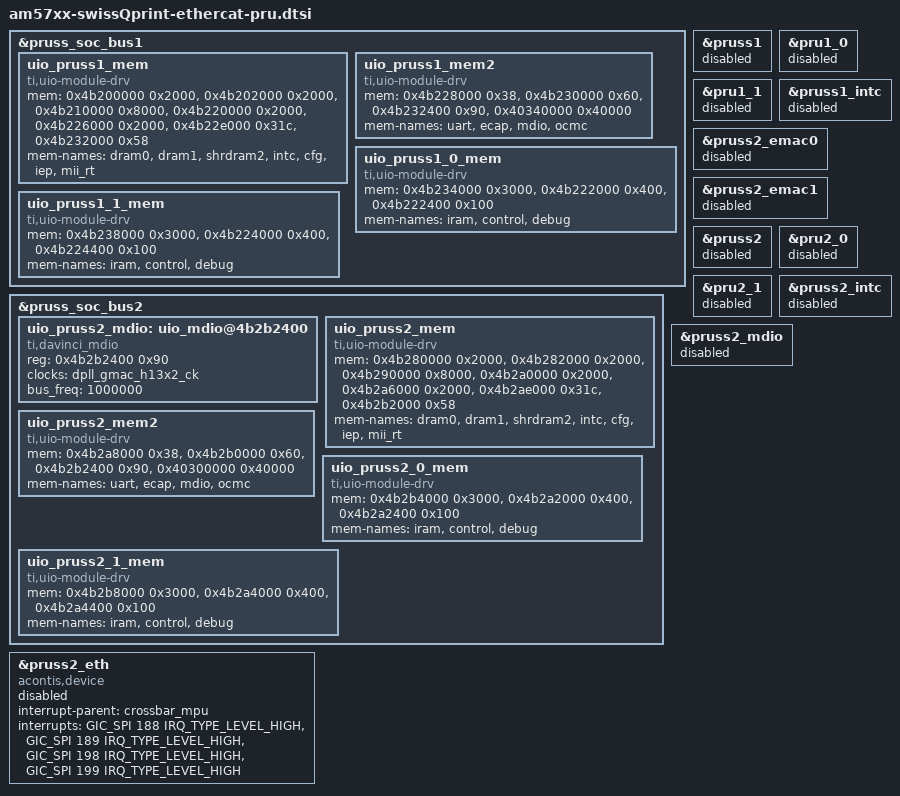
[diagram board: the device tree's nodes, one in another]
&pruss_soc_bus1 {
    uio_pruss1_mem: uio_pruss1_mem {
            compatible = "ti,uio-module-drv";
            mem = <0x4b200000 0x2000>,
                    <0x4b202000 0x2000>,
                    <0x4b210000 0x8000>,
                    <0x4b220000 0x2000>,
                    <0x4b226000 0x2000>,
                    <0x4b22e000 0x31c>,
                    <0x4b232000 0x58>;
            mem-names = "dram0", "dram1", "shrdram2", "intc", "cfg",
                        "iep", "mii_rt";
            status = "okay";
    };
    uio_pruss1_mem2: uio_pruss1_mem2 {
            compatible = "ti,uio-module-drv";
            mem = <0x4b228000 0x38>,
                    <0x4b230000 0x60>,
                    <0x4b232400 0x90>,
                    <0x40340000 0x40000>;
            mem-names = "uart", "ecap", "mdio", "ocmc";
            status = "okay";
    };
    uio_pruss1_0_mem: uio_pruss1_0_mem {
            compatible = "ti,uio-module-drv";
            mem = <0x4b234000 0x3000>,
                    <0x4b222000 0x400>,
                    <0x4b222400 0x100>;
            mem-names = "iram", "control", "debug";
            status = "okay";
    };
    uio_pruss1_1_mem: uio_pruss1_1_mem {
            compatible = "ti,uio-module-drv";
            mem = <0x4b238000 0x3000>,
                    <0x4b224000 0x400>,
                    <0x4b224400 0x100>;
            mem-names = "iram", "control", "debug";
            status = "okay";
    };
};

&pruss1 {
    status = "disabled";
};

&pru1_0 {
    status = "disabled";
};

&pru1_1 {
    status = "disabled";
};

&pruss1_intc {
    status = "disabled";
};

&pruss_soc_bus2 {
    uio_pruss2_mdio: uio_mdio@4b2b2400 {
        compatible = "ti,davinci_mdio";
        reg = <0x4b2b2400 0x90>;
        #address-cells = <1>;
        #size-cells = <0>;
        clocks = <&dpll_gmac_h13x2_ck>;
        clock-names = "fck";
        bus_freq = <1000000>;
        status = "okay";
    };

    uio_pruss2_mem: uio_pruss2_mem {
        compatible = "ti,uio-module-drv";
        mem = <0x4b280000 0x2000>,
                <0x4b282000 0x2000>,
                <0x4b290000 0x8000>,
                <0x4b2a0000 0x2000>,
                <0x4b2a6000 0x2000>,
                <0x4b2ae000 0x31c>,
                <0x4b2b2000 0x58>;
        mem-names = "dram0", "dram1", "shrdram2", "intc", "cfg",
                "iep", "mii_rt";
        status = "okay";
    };
    uio_pruss2_mem2: uio_pruss2_mem2 {
        compatible = "ti,uio-module-drv";
        mem = <0x4b2a8000 0x38>,
                <0x4b2b0000 0x60>,
                <0x4b2b2400 0x90>,
                <0x40300000 0x40000>;
        mem-names = "uart", "ecap", "mdio", "ocmc";
        status = "okay";
    };
    uio_pruss2_0_mem: uio_pruss2_0_mem {
        compatible = "ti,uio-module-drv";
        mem = <0x4b2b4000 0x3000>,
                <0x4b2a2000 0x400>,
                <0x4b2a2400 0x100>;
        mem-names = "iram", "control", "debug";
        status = "okay";
    };
    uio_pruss2_1_mem: uio_pruss2_1_mem {
        compatible = "ti,uio-module-drv";
        mem = <0x4b2b8000 0x3000>,
                <0x4b2a4000 0x400>,
                <0x4b2a4400 0x100>;
        mem-names = "iram", "control", "debug";
        status = "okay";
    };
};


&pruss2_emac0 {
    status = "disabled";
};

&pruss2_emac1 {
    status = "disabled";
};

&pruss2 {
    status = "disabled";
};

&pru2_0 {
	status = "disabled";
};

&pru2_1 {
	status = "disabled";
};

&pruss2_intc {
    status = "disabled";
};

&pruss2_mdio {
    status = "disabled";
};

// acontis changes 
&pruss2_eth { 
    compatible = "acontis,device"; 
    status="disabled"; 
            
    interrupt-parent = <&crossbar_mpu>; 
            
    interrupts = <GIC_SPI 188 IRQ_TYPE_LEVEL_HIGH>, 
                 <GIC_SPI 189 IRQ_TYPE_LEVEL_HIGH>, 
                 <GIC_SPI 198 IRQ_TYPE_LEVEL_HIGH>, 
                 <GIC_SPI 199 IRQ_TYPE_LEVEL_HIGH>;
}; 
